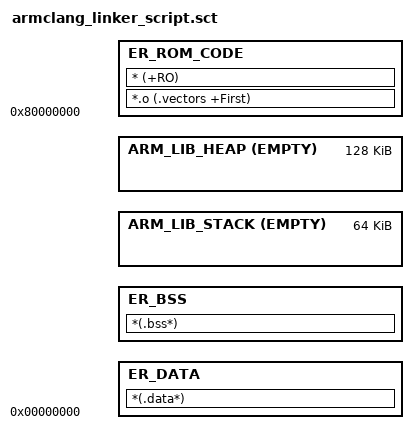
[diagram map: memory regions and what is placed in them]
#! armclang --target=aarch64-arm-none-eabi -march=armv8-r -E -x c
/*
 * Copyright (c) 2021-2025 Arm Limited. All rights reserved.
 *
 * Licensed under the Apache License, Version 2.0 (the "License");
 * you may not use this file except in compliance with the License.
 * You may obtain a copy of the License at
 *
 *     http://www.apache.org/licenses/LICENSE-2.0
 *
 * Unless required by applicable law or agreed to in writing, software
 * distributed under the License is distributed on an "AS IS" BASIS,
 * WITHOUT WARRANTIES OR CONDITIONS OF ANY KIND, either express or implied.
 * See the License for the specific language governing permissions and
 * limitations under the License.
 */

#define  __ROM_START           0x80000000
#define  __RAM_START           0x00000000
#define  __ROM_SIZE            0x00400000
#define  __RAM_SIZE            0x10000000
#define  __STACK_SIZE          0x00010000
#define  __HEAP_SIZE           0x00020000

;===============================================================================
;  LOAD REGION:  on-board flash 0x80000000 (4 MB)
;===============================================================================
LOAD_REGION  __ROM_START
{
    ;-- Code + RO data ---------------------------------------------------------
    ER_ROM_CODE __ROM_START ALIGN 8
    {
        *.o (.vectors +First)
        * (+RO)                ; All read only
    }
}

LOAD_REGION_1  +0 ALIGN 32
{
    ;-- Data + Shared Ram between cores ----------------------------------------
    ER_DATA __RAM_START ALIGN 8
    {
        *(.data*)
    }

    ;-- Zero-initialised data --------------------------------------------------
    ER_BSS +0 ALIGN 8
    {
        *(.bss*)
    }

    ;-- Stack ------------------------------------------------------------------
    ARM_LIB_STACK +0 ALIGN 32 EMPTY (__STACK_SIZE) {
    }

    ;-- Heap -------------------------------------------------------------------
    ARM_LIB_HEAP +0 ALIGN 8 EMPTY (__HEAP_SIZE) {
    }
}
